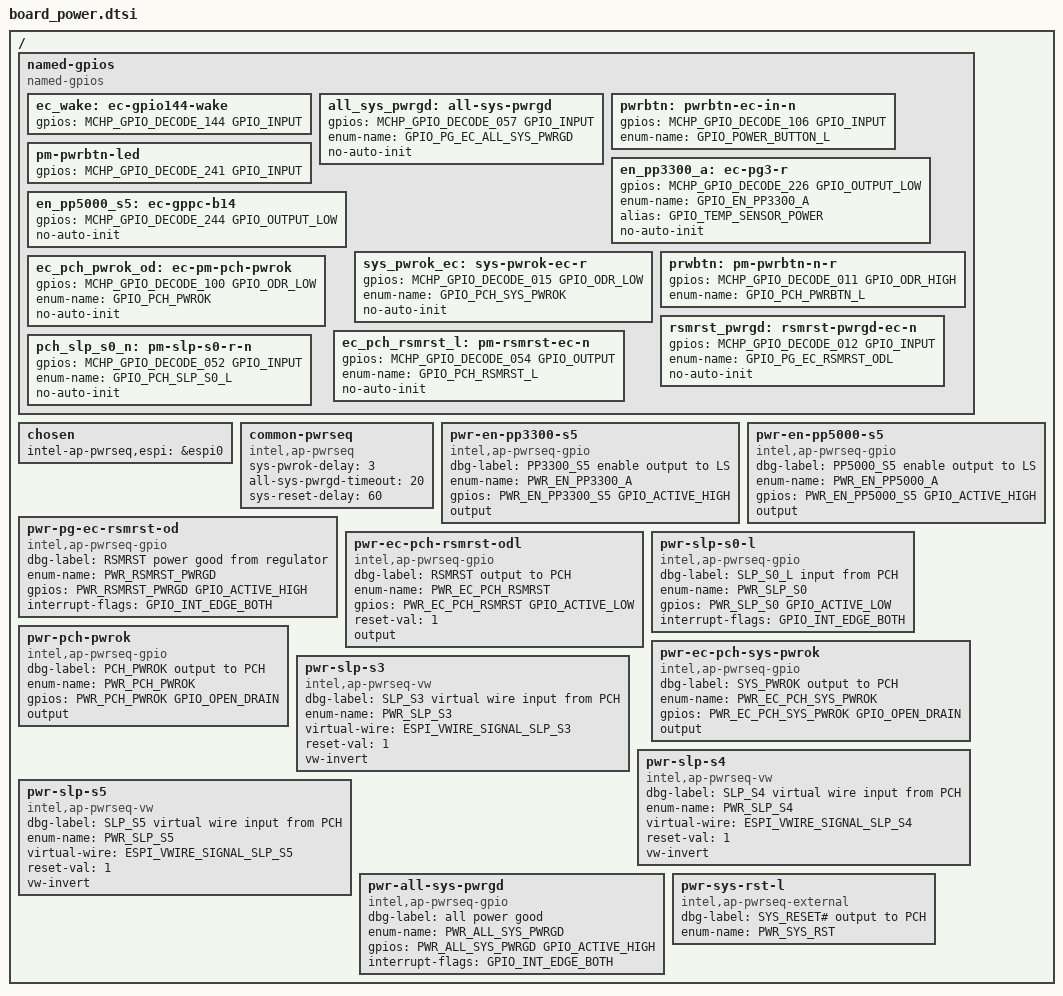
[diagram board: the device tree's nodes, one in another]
/* Copyright 2024 The ChromiumOS Authors
 * Use of this source code is governed by a BSD-style license that can be
 * found in the LICENSE file.
 */

#include <dt-bindings/gpio/microchip-xec-gpio.h>
#include <mchp_emul.dts>

/* Power Signals */
#define PWR_EN_PP3300_S5 MCHP_GPIO_DECODE_226
#define PWR_EN_PP5000_S5 MCHP_GPIO_DECODE_244
#define PWR_RSMRST_PWRGD MCHP_GPIO_DECODE_012
#define PWR_EC_PCH_RSMRST MCHP_GPIO_DECODE_054
#define PWR_SLP_S0 MCHP_GPIO_DECODE_052
#define PWR_PCH_PWROK MCHP_GPIO_DECODE_100
#define PWR_EC_PCH_SYS_PWROK MCHP_GPIO_DECODE_015
#define PWR_ALL_SYS_PWRGD MCHP_GPIO_DECODE_057

/ {

	named-gpios {
		compatible = "named-gpios";

		ec_wake: ec-gpio144-wake {
			gpios = <MCHP_GPIO_DECODE_144 GPIO_INPUT>;
		};
		all_sys_pwrgd: all-sys-pwrgd {
			gpios = <MCHP_GPIO_DECODE_057 GPIO_INPUT>;
			enum-name = "GPIO_PG_EC_ALL_SYS_PWRGD";
		};
		pwrbtn: pwrbtn-ec-in-n {
			gpios = <MCHP_GPIO_DECODE_106 GPIO_INPUT>;
			enum-name = "GPIO_POWER_BUTTON_L";
		};
		en_pp3300_a: ec-pg3-r {
			gpios = <MCHP_GPIO_DECODE_226 GPIO_OUTPUT_LOW>;
			enum-name = "GPIO_EN_PP3300_A";
			alias = "GPIO_TEMP_SENSOR_POWER";
		};
		pm-pwrbtn-led {
			gpios = <MCHP_GPIO_DECODE_241 GPIO_INPUT>;
		};
		en_pp5000_s5: ec-gppc-b14 {
			gpios = <MCHP_GPIO_DECODE_244 GPIO_OUTPUT_LOW>;
		};
		sys_pwrok_ec: sys-pwrok-ec-r {
			gpios = <MCHP_GPIO_DECODE_015 GPIO_ODR_LOW>;
			enum-name = "GPIO_PCH_SYS_PWROK";
		};
		prwbtn: pm-pwrbtn-n-r {
			gpios = <MCHP_GPIO_DECODE_011 GPIO_ODR_HIGH>;
			enum-name = "GPIO_PCH_PWRBTN_L";
		};
		ec_pch_pwrok_od: ec-pm-pch-pwrok {
			gpios = <MCHP_GPIO_DECODE_100 GPIO_ODR_LOW>;
			enum-name = "GPIO_PCH_PWROK";
		};
		rsmrst_pwrgd: rsmrst-pwrgd-ec-n {
			gpios = <MCHP_GPIO_DECODE_012 GPIO_INPUT>;
			enum-name = "GPIO_PG_EC_RSMRST_ODL";
		};
		ec_pch_rsmrst_l: pm-rsmrst-ec-n {
			gpios = <MCHP_GPIO_DECODE_054 GPIO_OUTPUT>;
			enum-name = "GPIO_PCH_RSMRST_L";
		};
		pch_slp_s0_n: pm-slp-s0-r-n {
			gpios = <MCHP_GPIO_DECODE_052 GPIO_INPUT>;
			enum-name = "GPIO_PCH_SLP_S0_L";
		};
	};

	chosen {
		intel-ap-pwrseq,espi = &espi0;
	};
	
	common-pwrseq {
		compatible = "intel,ap-pwrseq";

		sys-pwrok-delay = <3>;
		all-sys-pwrgd-timeout = <20>;
		sys-reset-delay = <60>;
	};

	pwr-en-pp3300-s5 {
		compatible = "intel,ap-pwrseq-gpio";
		dbg-label = "PP3300_S5 enable output to LS";
		enum-name = "PWR_EN_PP3300_A";
		gpios = <PWR_EN_PP3300_S5 GPIO_ACTIVE_HIGH>;
		output;
	};
	pwr-en-pp5000-s5 {
		compatible = "intel,ap-pwrseq-gpio";
		dbg-label = "PP5000_S5 enable output to LS";
		enum-name = "PWR_EN_PP5000_A";
		gpios = <PWR_EN_PP5000_S5 GPIO_ACTIVE_HIGH>;
		output;
	};
	pwr-pg-ec-rsmrst-od {
		compatible = "intel,ap-pwrseq-gpio";
		dbg-label = "RSMRST power good from regulator";
		enum-name = "PWR_RSMRST_PWRGD";
		gpios = <PWR_RSMRST_PWRGD GPIO_ACTIVE_HIGH>;
		interrupt-flags = <GPIO_INT_EDGE_BOTH>;
	};
	pwr-ec-pch-rsmrst-odl {
		compatible = "intel,ap-pwrseq-gpio";
		dbg-label = "RSMRST output to PCH";
		enum-name = "PWR_EC_PCH_RSMRST";
		gpios = <PWR_EC_PCH_RSMRST GPIO_ACTIVE_LOW>;
		reset-val = <1>;
		output;
	};
	pwr-slp-s0-l {
		compatible = "intel,ap-pwrseq-gpio";
		dbg-label = "SLP_S0_L input from PCH";
		enum-name = "PWR_SLP_S0";
		gpios = <PWR_SLP_S0 GPIO_ACTIVE_LOW>;
		interrupt-flags = <GPIO_INT_EDGE_BOTH>;
	};
	pwr-pch-pwrok {
		compatible = "intel,ap-pwrseq-gpio";
		dbg-label = "PCH_PWROK output to PCH";
		enum-name = "PWR_PCH_PWROK";
		gpios = <PWR_PCH_PWROK GPIO_OPEN_DRAIN>;
		output;
	};
	pwr-ec-pch-sys-pwrok {
		compatible = "intel,ap-pwrseq-gpio";
		dbg-label = "SYS_PWROK output to PCH";
		enum-name = "PWR_EC_PCH_SYS_PWROK";
		gpios = <PWR_EC_PCH_SYS_PWROK GPIO_OPEN_DRAIN>;
		output;
	};
	pwr-slp-s3 {
		compatible = "intel,ap-pwrseq-vw";
		dbg-label = "SLP_S3 virtual wire input from PCH";
		enum-name = "PWR_SLP_S3";
		virtual-wire = "ESPI_VWIRE_SIGNAL_SLP_S3";
		reset-val = <1>;
		vw-invert;
	};
	pwr-slp-s4 {
		compatible = "intel,ap-pwrseq-vw";
		dbg-label = "SLP_S4 virtual wire input from PCH";
		enum-name = "PWR_SLP_S4";
		virtual-wire = "ESPI_VWIRE_SIGNAL_SLP_S4";
		reset-val = <1>;
		vw-invert;
	};
	pwr-slp-s5 {
		compatible = "intel,ap-pwrseq-vw";
		dbg-label = "SLP_S5 virtual wire input from PCH";
		enum-name = "PWR_SLP_S5";
		virtual-wire = "ESPI_VWIRE_SIGNAL_SLP_S5";
		reset-val = <1>;
		vw-invert;
	};
	pwr-all-sys-pwrgd {
		compatible = "intel,ap-pwrseq-gpio";
		dbg-label = "all power good";
		enum-name = "PWR_ALL_SYS_PWRGD";
		gpios = <PWR_ALL_SYS_PWRGD GPIO_ACTIVE_HIGH>;
		interrupt-flags = <GPIO_INT_EDGE_BOTH>;
	};
	pwr-sys-rst-l {
		compatible = "intel,ap-pwrseq-external";
		dbg-label = "SYS_RESET# output to PCH";
		enum-name = "PWR_SYS_RST";
	};
};


/*
 * Because the power signals directly reference the GPIOs,
 * the correspinding named-gpios need to have no-auto-init set.
 */
&en_pp3300_a {
	no-auto-init;
};
&en_pp5000_s5 {
	no-auto-init;
};
&rsmrst_pwrgd {
	no-auto-init;
};
&ec_pch_rsmrst_l {
	no-auto-init;
};
&pch_slp_s0_n {
	no-auto-init;
};
&ec_pch_pwrok_od {
	no-auto-init;
};
&sys_pwrok_ec {
	no-auto-init;
};
&all_sys_pwrgd {
	no-auto-init;
};
